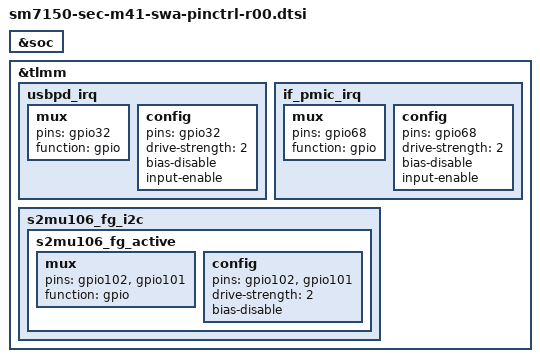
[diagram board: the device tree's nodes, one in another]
/* Copyright (c) 2019, The Linux Foundation. All rights reserved. 

* 

* This program is free software; you can redistribute it and/or modify 

* it under the terms of the GNU General Public License version 2 and 

* only version 2 as published by the Free Software Foundation. 

* 

* This program is distributed in the hope that it will be useful, 

* but WITHOUT ANY WARRANTY; without even the implied warranty of 

* MERCHANTABILITY or FITNESS FOR A PARTICULAR PURPOSE.  See the 

* GNU General Public License for more details. 

*/ 


&soc {
	
};

&tlmm {
    usbpd_irq: usbpd_irq {
		mux {
			pins = "gpio32";
	 		function = "gpio";
	 	};
		config {
	 		pins = "gpio32";
			drive-strength = <2>;
			bias-disable;
			input-enable;
	 	};
	};
	
	if_pmic_irq: if_pmic_irq {
		mux {
			pins = "gpio68";
			function = "gpio";
		};
		config {
			pins = "gpio68";
			drive-strength = <2>;   /* 16 mA */
			bias-disable;
			input-enable;
		};
	};
	
	/* s2mu106_fg i2c */
	s2mu106_fg_i2c: s2mu106_fg_i2c {
		s2mu106_fg_active: s2mu106_fg_active {
			mux {
				pins = "gpio102", "gpio101";
				function = "gpio";
			};

			config {
				pins = "gpio102", "gpio101";
				drive-strength = <2>;
				bias-disable;
			};
		};
	};
};

